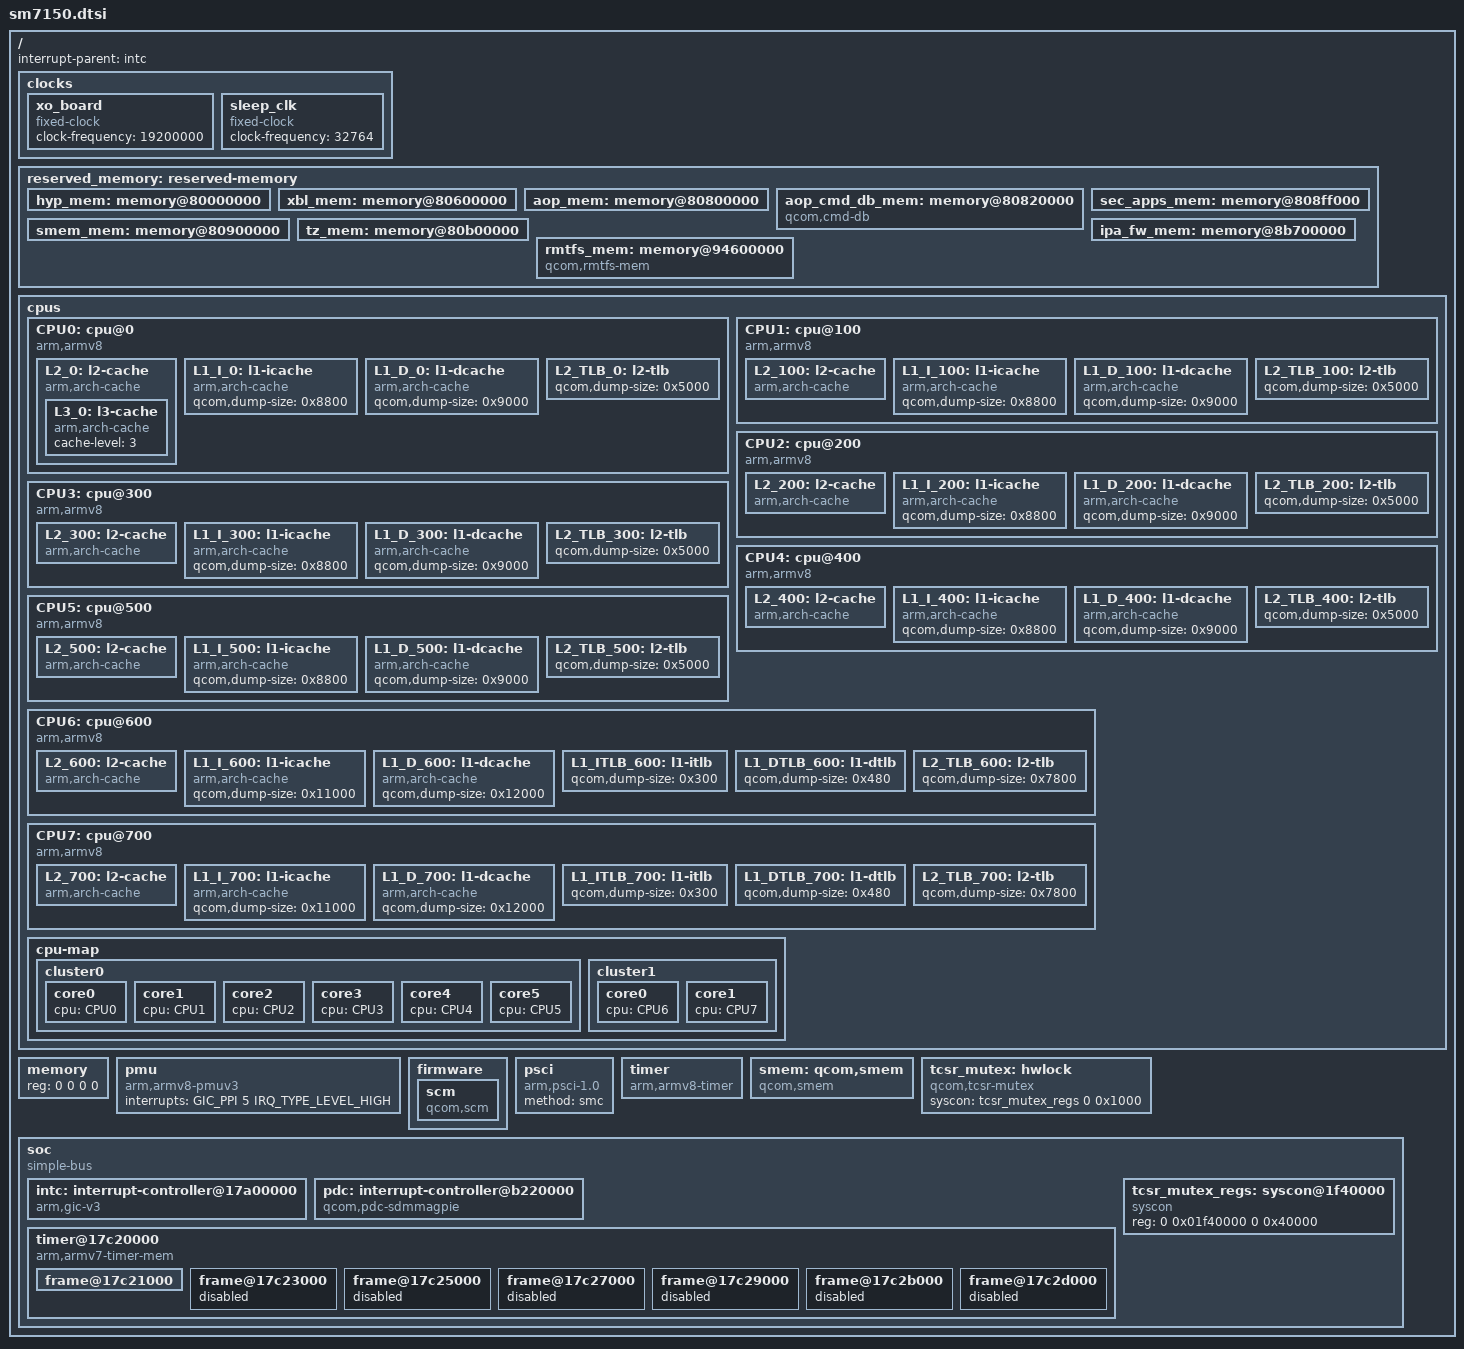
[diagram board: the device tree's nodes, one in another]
// SPDX-License-Identifier: GPL-2.0-only
/*
 * Copyright (c) 2021, FIXME
 */

#include <dt-bindings/clock/qcom,gcc-sm7150.h>
#include <dt-bindings/clock/qcom,rpmcc.h>
#include <dt-bindings/gpio/gpio.h>
#include <dt-bindings/interrupt-controller/arm-gic.h>

/ {
	interrupt-parent = <&intc>;

	#address-cells = <2>;
	#size-cells = <2>;

	clocks {
		xo_board: xo_board {
			compatible = "fixed-clock";
			clock-frequency = <19200000>;
			#clock-cells = <0>;
		};

		sleep_clk: sleep_clk {
			compatible = "fixed-clock";
			clock-frequency = <32764>;
			#clock-cells = <0>;
		};
	};

	reserved_memory: reserved-memory {
		#address-cells = <2>;
		#size-cells = <2>;
		ranges;

		hyp_mem: memory@80000000 {
			reg = <0x0 0x80000000 0x0 0x600000>;
			no-map;
		};

		xbl_mem: memory@80600000 {
			reg = <0x0 0x80600000 0x0 0x200000>;
			no-map;
		};

		aop_mem: memory@80800000 {
			reg = <0x0 0x80800000 0x0 0x20000>;
			no-map;
		};

		aop_cmd_db_mem: memory@80820000 {
			reg = <0x0 0x80820000 0x0 0x20000>;
			compatible = "qcom,cmd-db";
			no-map;
		};

		sec_apps_mem: memory@808ff000 {
			reg = <0x0 0x808ff000 0x0 0x1000>;
			no-map;
		};

		smem_mem: memory@80900000 {
			reg = <0x0 0x80900000 0x0 0x200000>;
			no-map;
		};

		tz_mem: memory@80b00000 {
			reg = <0x0 0x80b00000 0x0 0x3900000>;
			no-map;
		};

		ipa_fw_mem: memory@8b700000 {
			reg = <0 0x8b700000 0 0x10000>;
			no-map;
		};

		rmtfs_mem: memory@94600000 {
			compatible = "qcom,rmtfs-mem";
			reg = <0x0 0x94600000 0x0 0x200000>;
			no-map;

			qcom,client-id = <1>;
			qcom,vmid = <15>;
		};
	};

	cpus {
		#address-cells = <2>;
		#size-cells = <0>;

		CPU0: cpu@0 {
			device_type = "cpu";
			compatible = "arm,armv8";
			reg = <0x0 0x0>;
			enable-method = "psci";
			capacity-dmips-mhz = <1024>;
			next-level-cache = <&L2_0>;
			#cooling-cells = <2>;
			L2_0: l2-cache {
			      compatible = "arm,arch-cache";
			      cache-level = <2>;
			      next-level-cache = <&L3_0>;

				L3_0: l3-cache {
				      compatible = "arm,arch-cache";
				      cache-level = <3>;
				};
			};

			L1_I_0: l1-icache {
				compatible = "arm,arch-cache";
				qcom,dump-size = <0x8800>;
			};

			L1_D_0: l1-dcache {
				compatible = "arm,arch-cache";
				qcom,dump-size = <0x9000>;
			};

			L2_TLB_0: l2-tlb {
				qcom,dump-size = <0x5000>;
			};
		};

		CPU1: cpu@100 {
			device_type = "cpu";
			compatible = "arm,armv8";
			reg = <0x0 0x100>;
			enable-method = "psci";
			capacity-dmips-mhz = <1024>;
			next-level-cache = <&L2_100>;
			#cooling-cells = <2>;
			L2_100: l2-cache {
			      compatible = "arm,arch-cache";
			      cache-level = <2>;
			      next-level-cache = <&L3_0>;
			};

			L1_I_100: l1-icache {
				compatible = "arm,arch-cache";
				qcom,dump-size = <0x8800>;
			};

			L1_D_100: l1-dcache {
				compatible = "arm,arch-cache";
				qcom,dump-size = <0x9000>;
			};

			L2_TLB_100: l2-tlb {
				qcom,dump-size = <0x5000>;
			};
		};


		CPU2: cpu@200 {
			device_type = "cpu";
			compatible = "arm,armv8";
			reg = <0x0 0x200>;
			enable-method = "psci";
			capacity-dmips-mhz = <1024>;
			next-level-cache = <&L2_200>;
			#cooling-cells = <2>;
			L2_200: l2-cache {
			      compatible = "arm,arch-cache";
			      cache-level = <2>;
			      next-level-cache = <&L3_0>;
			};

			L1_I_200: l1-icache {
				compatible = "arm,arch-cache";
				qcom,dump-size = <0x8800>;
			};

			L1_D_200: l1-dcache {
				compatible = "arm,arch-cache";
				qcom,dump-size = <0x9000>;
			};

			L2_TLB_200: l2-tlb {
				qcom,dump-size = <0x5000>;
			};
		};

		CPU3: cpu@300 {
			device_type = "cpu";
			compatible = "arm,armv8";
			reg = <0x0 0x300>;
			enable-method = "psci";
			capacity-dmips-mhz = <1024>;
			next-level-cache = <&L2_300>;
			#cooling-cells = <2>;
			L2_300: l2-cache {
			      compatible = "arm,arch-cache";
			      cache-level = <2>;
			      next-level-cache = <&L3_0>;
			};

			L1_I_300: l1-icache {
				compatible = "arm,arch-cache";
				qcom,dump-size = <0x8800>;
			};

			L1_D_300: l1-dcache {
				compatible = "arm,arch-cache";
				qcom,dump-size = <0x9000>;
			};

			L2_TLB_300: l2-tlb {
				qcom,dump-size = <0x5000>;
			};
		};

		CPU4: cpu@400 {
			device_type = "cpu";
			compatible = "arm,armv8";
			reg = <0x0 0x400>;
			enable-method = "psci";
			capacity-dmips-mhz = <1024>;
			next-level-cache = <&L2_400>;
			#cooling-cells = <2>;
			L2_400: l2-cache {
			      compatible = "arm,arch-cache";
			      cache-level = <2>;
			      next-level-cache = <&L3_0>;
			};

			L1_I_400: l1-icache {
				compatible = "arm,arch-cache";
				qcom,dump-size = <0x8800>;
			};

			L1_D_400: l1-dcache {
				compatible = "arm,arch-cache";
				qcom,dump-size = <0x9000>;
			};

			L2_TLB_400: l2-tlb {
				qcom,dump-size = <0x5000>;
			};
		};

		CPU5: cpu@500 {
			device_type = "cpu";
			compatible = "arm,armv8";
			reg = <0x0 0x500>;
			enable-method = "psci";
			capacity-dmips-mhz = <1024>;
			next-level-cache = <&L2_500>;
			#cooling-cells = <2>;
			L2_500: l2-cache {
			      compatible = "arm,arch-cache";
			      cache-level = <2>;
			      next-level-cache = <&L3_0>;
			};

			L1_I_500: l1-icache {
				compatible = "arm,arch-cache";
				qcom,dump-size = <0x8800>;
			};

			L1_D_500: l1-dcache {
				compatible = "arm,arch-cache";
				qcom,dump-size = <0x9000>;
			};

			L2_TLB_500: l2-tlb {
				qcom,dump-size = <0x5000>;
			};
		};

		CPU6: cpu@600 {
			device_type = "cpu";
			compatible = "arm,armv8";
			reg = <0x0 0x600>;
			enable-method = "psci";
			capacity-dmips-mhz = <1740>;
			next-level-cache = <&L2_600>;
			#cooling-cells = <2>;
			L2_600: l2-cache {
			      compatible = "arm,arch-cache";
			      cache-level = <2>;
			      next-level-cache = <&L3_0>;
			      qcom,dump-size = <0x48000>;
			};

			L1_I_600: l1-icache {
				compatible = "arm,arch-cache";
				qcom,dump-size = <0x11000>;
			};

			L1_D_600: l1-dcache {
				compatible = "arm,arch-cache";
				qcom,dump-size = <0x12000>;
			};

			L1_ITLB_600: l1-itlb {
				qcom,dump-size = <0x300>;
			};

			L1_DTLB_600: l1-dtlb {
				qcom,dump-size = <0x480>;
			};

			L2_TLB_600: l2-tlb {
				qcom,dump-size = <0x7800>;
			};
		};

		CPU7: cpu@700 {
			device_type = "cpu";
			compatible = "arm,armv8";
			reg = <0x0 0x700>;
			enable-method = "psci";
			capacity-dmips-mhz = <1740>;
			next-level-cache = <&L2_700>;
			#cooling-cells = <2>;
			L2_700: l2-cache {
			      compatible = "arm,arch-cache";
			      cache-level = <2>;
			      next-level-cache = <&L3_0>;
			      qcom,dump-size = <0x48000>;
			};

			L1_I_700: l1-icache {
				compatible = "arm,arch-cache";
				qcom,dump-size = <0x11000>;
			};

			L1_D_700: l1-dcache {
				compatible = "arm,arch-cache";
				qcom,dump-size = <0x12000>;
			};

			L1_ITLB_700: l1-itlb {
				qcom,dump-size = <0x300>;
			};

			L1_DTLB_700: l1-dtlb {
				qcom,dump-size = <0x480>;
			};

			L2_TLB_700: l2-tlb {
				qcom,dump-size = <0x7800>;
			};
		};

		cpu-map {
			cluster0 {
				core0 {
					cpu = <&CPU0>;
				};

				core1 {
					cpu = <&CPU1>;
				};

				core2 {
					cpu = <&CPU2>;
				};

				core3 {
					cpu = <&CPU3>;
				};

				core4 {
					cpu = <&CPU4>;
				};

				core5 {
					cpu = <&CPU5>;
				};

			};

			cluster1 {
				core0 {
					cpu = <&CPU6>;
				};

				core1 {
					cpu = <&CPU7>;
				};
			};
		};
	};

	memory {
		device_type = "memory";
		/* We expect the bootloader to fill in the size */
		reg = <0 0 0 0>;
	};

	pmu {
		compatible = "arm,armv8-pmuv3";
		interrupts = <GIC_PPI 5 IRQ_TYPE_LEVEL_HIGH>;
	};

	firmware {
		scm {
			compatible = "qcom,scm";
		};
	};

	psci {
		compatible = "arm,psci-1.0";
		method = "smc";
	};

	timer {
		compatible = "arm,armv8-timer";
		interrupts = <GIC_PPI 1 IRQ_TYPE_LEVEL_LOW>,
			     <GIC_PPI 2 IRQ_TYPE_LEVEL_LOW>,
			     <GIC_PPI 3 IRQ_TYPE_LEVEL_LOW>,
			     <GIC_PPI 0 IRQ_TYPE_LEVEL_LOW>;
	};

	smem: qcom,smem {
		compatible = "qcom,smem";
		memory-region = <&smem_mem>;
		hwlocks = <&tcsr_mutex 3>;
	};

	tcsr_mutex: hwlock {
		compatible = "qcom,tcsr-mutex";
		syscon = <&tcsr_mutex_regs 0 0x1000>;
		#hwlock-cells = <1>;
	};

	soc: soc {
		compatible = "simple-bus";
		#address-cells = <1>;
		#size-cells = <1>;
		ranges = <0 0 0 0xffffffff>;

		intc: interrupt-controller@17a00000 {
		compatible = "arm,gic-v3";
			#interrupt-cells = <3>;
			interrupt-controller;
			#redistributor-regions = <1>;
			redistributor-stride = <0x0 0x20000>;
			reg = <0x17a00000 0x10000>,     /* GICD */
			<0x17a60000 0x100000>;    /* GICR * 8 */
			interrupts = <GIC_PPI 9 IRQ_TYPE_LEVEL_HIGH>;
			interrupt-parent = <&intc>;
		};

		pdc: interrupt-controller@b220000 {
			compatible = "qcom,pdc-sdmmagpie";
			reg = <0xb220000 0x400>;
			#interrupt-cells = <3>;
			interrupt-parent = <&intc>;
			interrupt-controller;
		};

		timer@17c20000{
			#address-cells = <1>;
			#size-cells = <1>;
			ranges;
			compatible = "arm,armv7-timer-mem";
			reg = <0x17c20000 0x1000>;
			clock-frequency = <19200000>;

			frame@17c21000 {
				frame-number = <0>;
				interrupts = <GIC_SPI 8 IRQ_TYPE_LEVEL_HIGH>,
					     <GIC_SPI 6 IRQ_TYPE_LEVEL_HIGH>;
				reg = <0x17c21000 0x1000>,
				      <0x17c22000 0x1000>;
			};

			frame@17c23000 {
				frame-number = <1>;
				interrupts = <GIC_SPI 9 IRQ_TYPE_LEVEL_HIGH>;
				reg = <0x17c23000 0x1000>;
				status = "disabled";
			};

			frame@17c25000 {
				frame-number = <2>;
				interrupts = <GIC_SPI 10 IRQ_TYPE_LEVEL_HIGH>;
				reg = <0x17c25000 0x1000>;
				status = "disabled";
			};

			frame@17c27000 {
				frame-number = <3>;
				interrupts = <GIC_SPI 11 IRQ_TYPE_LEVEL_HIGH>;
				reg = <0x17c27000 0x1000>;
				status = "disabled";
			};

			frame@17c29000 {
				frame-number = <4>;
				interrupts = <GIC_SPI 12 IRQ_TYPE_LEVEL_HIGH>;
				reg = <0x17c29000 0x1000>;
				status = "disabled";
			};

			frame@17c2b000 {
				frame-number = <5>;
				interrupts = <GIC_SPI 13 IRQ_TYPE_LEVEL_HIGH>;
				reg = <0x17c2b000 0x1000>;
				status = "disabled";
			};

			frame@17c2d000 {
				frame-number = <6>;
				interrupts = <GIC_SPI 14 IRQ_TYPE_LEVEL_HIGH>;
				reg = <0x17c2d000 0x1000>;
				status = "disabled";
			};
		};

		tcsr_mutex_regs: syscon@1f40000 {
			compatible = "syscon";
			reg = <0 0x01f40000 0 0x40000>;
		};
	};
};
